# NPCX498S register map
File version: 1.0
Registers are 8-bit, read-write, reset 0x0 unless marked. A register's access mark holds for its fields unless they carry their own. Offsets are from the block's base; [hi:lo] are bit positions.

## MFT16_1
Base 0x400E1000
Same registers: MFT16_2 0x400E3000, MFT16_3 0x400E5000
0x00 TnCNT1 16-bit (reset mask 0xFF) — Timer/Counter 1 Register (TnCNT1)
0x02 TnCRA 16-bit (reset mask 0xFF) — Reload/Capture A Register (TnCRA)
0x04 TnCRB 16-bit (reset mask 0xFF) — Reload/Capture B Register (TnCRB)
0x06 TnCNT2 16-bit (reset mask 0xFF) — Timer/Counter 2 Register (TnCNT2)
0x08 TnPRSC — Clock Prescaler Register (TnPRSC)
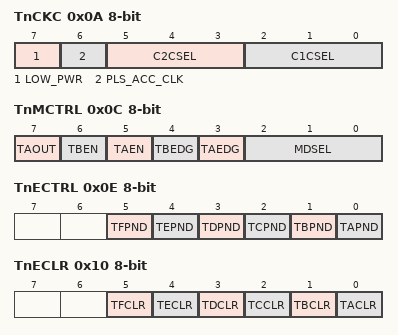
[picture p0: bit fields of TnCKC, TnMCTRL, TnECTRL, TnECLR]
0x0A TnCKC — Clock Unit Control Register (TnCKC)
  [7] LOW_PWR — Low-Power Mode Select
  [6] PLS_ACC_CLK — Pulse Accumulate Clock Select
  [5:3] C2CSEL — Counter 2 Clock Select
  [2:0] C1CSEL — Counter 1 Clock Select
0x0C TnMCTRL — Timer Mode Control Register (TnMCTRL)
  [7] TAOUT — TAn Output Data
  [6] TBEN — TBn Enable
  [5] TAEN — TAn Enable
  [4] TBEDG — TBn Edge Polarity
  [3] TAEDG — TAn Edge Polarity
  [2:0] MDSEL — Mode Select
0x0E TnECTRL — Timer Event Control Register (TnECTRL)
  [5] TFPND — Timer Event Source F Pending
  [4] TEPND — Timer Event Source E Pending
  [3] TDPND — Timer Event Source D Pending
  [2] TCPND — Timer Event Source C Pending
  [1] TBPND — Timer Event Source B Pending
  [0] TAPND — Timer Event Source A Pending
0x10 TnECLR — Timer Event Clear Register (TnECLR)
  [5] TFCLR — Timer Pending F Clear
  [4] TECLR — Timer Pending E Clear
  [3] TDCLR — Timer Pending D Clear
  [2] TCCLR — Timer Pending C Clear
  [1] TBCLR — Timer Pending B Clear
  [0] TACLR — Timer Pending A Clear
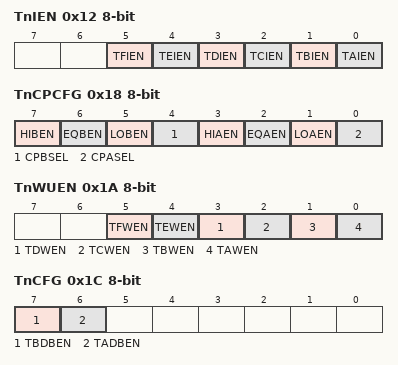
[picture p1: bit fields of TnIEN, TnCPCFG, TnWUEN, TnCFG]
0x12 TnIEN — Timer Interrupt Enable Register (TnIEN)
  [5] TFIEN — Timer Interrupt F Enable
  [4] TEIEN — Timer Interrupt E Enable
  [3] TDIEN — Timer Interrupt D Enable
  [2] TCIEN — Timer Interrupt C Enable
  [1] TBIEN — Timer Interrupt B Enable
  [0] TAIEN — Timer Interrupt A Enable
0x14 TnCPA 16-bit (reset mask 0xFF) — Compare A Register (TnCPA)
0x16 TnCPB 16-bit (reset mask 0xFF) — Compare B Register (TnCPB)
0x18 TnCPCFG — Compare Configuration Register (TnCPCFG)
  [7] HIBEN — High Indication Enable for Comparator B
  [6] EQBEN — Equal Indication Enable for Comparator B
  [5] LOBEN — Low Indication Enable for Comparator B
  [4] CPBSEL — Compare Function B Select
  [3] HIAEN — High Indication Enable for Comparator A
  [2] EQAEN — Equal Indication Enable for Comparator A
  [1] LOAEN — Low Indication Enable for Comparator A
  [0] CPASEL — Compare Function A Select
0x1A TnWUEN — Timer Wake-Up Enable Register (TnWUEN)
  [5] TFWEN — Timer Wake-Up F Enable
  [4] TEWEN — Timer Wake-Up E Enable
  [3] TDWEN — Timer Wake-Up D Enable
  [2] TCWEN — Timer Wake-Up C Enable
  [1] TBWEN — Timer Wake-Up B Enable
  [0] TAWEN — Timer Wake-Up A Enable
0x1C TnCFG — Timer Configuration Register (TnCFG)
  [7] TBDBEN — TBn Debounce Enable
  [6] TADBEN — TAn Debounce Enable

## MIWU0
Base 0x400BB000
Same registers: MIWU1 0x400BD000, MIWU2 0x400BF000
0x00 WKEDGnx0 — Edge Detection nx Register (WKEDGnx)
0x01 WKAEDGnx0 — Any Edge Detection nx Register (WKAEDGnx)
0x02 WKMODnx0 — Wake-Up Detection Mode nx Register (WKMODnx)
0x03 WKPNDnx0 — Pending nx Register (WKPNDnx)
0x04 WKPCLnx0 — Pending Clear nx Register (WKPCLnx)
0x05 WKENnx0 — Enable nx Register (WKENnx)
0x06 WKSTnx0 — Wake-Up Status nx Register (WKSTnx)
0x07 WKINENnx0 — Wake-Up Input Enable nx Register (WKINENnx)
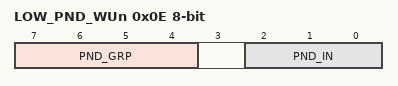
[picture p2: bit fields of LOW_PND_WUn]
0x0E LOW_PND_WUn — Lowest Pending Wake-Up Register (LOW_PND_WUn)
  [7:4] PND_GRP — Pending Group
  [2:0] PND_IN — Pending Input
0x10 WKEDGnx2 — Edge Detection nx Register (WKEDGnx)
0x11 WKAEDGnx2 — Any Edge Detection nx Register (WKAEDGnx)
0x12 WKMODnx2 — Wake-Up Detection Mode nx Register (WKMODnx)
0x13 WKPNDnx2 — Pending nx Register (WKPNDnx)
0x14 WKPCLnx2 — Pending Clear nx Register (WKPCLnx)
0x15 WKENnx2 — Enable nx Register (WKENnx)
0x16 WKSTnx2 — Wake-Up Status nx Register (WKSTnx)
0x17 WKINENnx2 — Wake-Up Input Enable nx Register (WKINENnx)
0x20 WKEDGnx4 — Edge Detection nx Register (WKEDGnx)
0x21 WKAEDGnx4 — Any Edge Detection nx Register (WKAEDGnx)
0x22 WKMODnx4 — Wake-Up Detection Mode nx Register (WKMODnx)
0x23 WKPNDnx4 — Pending nx Register (WKPNDnx)
0x24 WKPCLnx4 — Pending Clear nx Register (WKPCLnx)
0x25 WKENnx4 — Enable nx Register (WKENnx)
0x26 WKSTnx4 — Wake-Up Status nx Register (WKSTnx)
0x27 WKINENnx4 — Wake-Up Input Enable nx Register (WKINENnx)
0x30 WKEDGnx6 — Edge Detection nx Register (WKEDGnx)
0x31 WKAEDGnx6 — Any Edge Detection nx Register (WKAEDGnx)
0x32 WKMODnx6 — Wake-Up Detection Mode nx Register (WKMODnx)
0x33 WKPNDnx6 — Pending nx Register (WKPNDnx)
0x34 WKPCLnx6 — Pending Clear nx Register (WKPCLnx)
0x35 WKENnx6 — Enable nx Register (WKENnx)
0x36 WKSTnx6 — Wake-Up Status nx Register (WKSTnx)
0x37 WKINENnx6 — Wake-Up Input Enable nx Register (WKINENnx)
0x40 WKEDGnx1 — Edge Detection nx Register (WKEDGnx)
0x41 WKAEDGnx1 — Any Edge Detection nx Register (WKAEDGnx)
0x42 WKMODnx1 — Wake-Up Detection Mode nx Register (WKMODnx)
0x43 WKPNDnx1 — Pending nx Register (WKPNDnx)
0x44 WKPCLnx1 — Pending Clear nx Register (WKPCLnx)
0x45 WKENnx1 — Enable nx Register (WKENnx)
0x46 WKSTnx1 — Wake-Up Status nx Register (WKSTnx)
0x47 WKINENnx1 — Wake-Up Input Enable nx Register (WKINENnx)
0x50 WKEDGnx3 — Edge Detection nx Register (WKEDGnx)
0x51 WKAEDGnx3 — Any Edge Detection nx Register (WKAEDGnx)
0x52 WKMODnx3 — Wake-Up Detection Mode nx Register (WKMODnx)
0x53 WKPNDnx3 — Pending nx Register (WKPNDnx)
0x54 WKPCLnx3 — Pending Clear nx Register (WKPCLnx)
0x55 WKENnx3 — Enable nx Register (WKENnx)
0x56 WKSTnx3 — Wake-Up Status nx Register (WKSTnx)
0x57 WKINENnx3 — Wake-Up Input Enable nx Register (WKINENnx)
0x60 WKEDGnx5 — Edge Detection nx Register (WKEDGnx)
0x61 WKAEDGnx5 — Any Edge Detection nx Register (WKAEDGnx)
0x62 WKMODnx5 — Wake-Up Detection Mode nx Register (WKMODnx)
0x63 WKPNDnx5 — Pending nx Register (WKPNDnx)
0x64 WKPCLnx5 — Pending Clear nx Register (WKPCLnx)
0x65 WKENnx5 — Enable nx Register (WKENnx)
0x66 WKSTnx5 — Wake-Up Status nx Register (WKSTnx)
0x67 WKINENnx5 — Wake-Up Input Enable nx Register (WKINENnx)
0x70 WKEDGnx7 — Edge Detection nx Register (WKEDGnx)
0x71 WKAEDGnx7 — Any Edge Detection nx Register (WKAEDGnx)
0x72 WKMODnx7 — Wake-Up Detection Mode nx Register (WKMODnx)
0x73 WKPNDnx7 — Pending nx Register (WKPNDnx)
0x74 WKPCLnx7 — Pending Clear nx Register (WKPCLnx)
0x75 WKENnx7 — Enable nx Register (WKENnx)
0x76 WKSTnx7 — Wake-Up Status nx Register (WKSTnx)
0x77 WKINENnx7 — Wake-Up Input Enable nx Register (WKINENnx)
